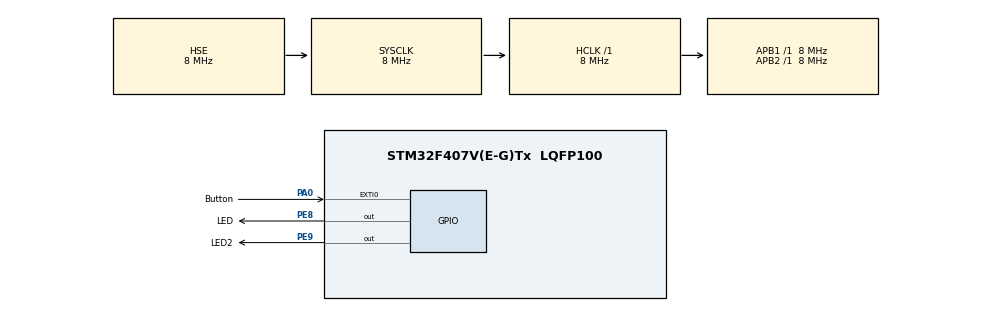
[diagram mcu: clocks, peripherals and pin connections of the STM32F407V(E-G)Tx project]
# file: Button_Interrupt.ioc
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Mcu.Family=STM32F4
Mcu.Name=STM32F407V(E-G)Tx
Mcu.Package=LQFP100
NVIC.EXTI0_IRQn=true\:0\:0\:false\:false\:true\:true\:true\:true
NVIC.PriorityGroup=NVIC_PRIORITYGROUP_4
PA0-WKUP.GPIO_Label=Button
PA0-WKUP.GPIO_ModeDefaultEXTI=GPIO_MODE_IT_RISING_FALLING
PA0-WKUP.GPIO_PuPd=GPIO_PULLDOWN
PA0-WKUP.Signal=GPXTI0
PA13.Mode=Serial_Wire
PA13.Signal=SYS_JTMS-SWDIO
PA14.Mode=Serial_Wire
PA14.Signal=SYS_JTCK-SWCLK
PE8.GPIO_Label=LED
PE8.Signal=GPIO_Output
PE9.GPIO_Label=LED2
PE9.Signal=GPIO_Output
PH0-OSC_IN.Mode=HSE-External-Oscillator
PH0-OSC_IN.Signal=RCC_OSC_IN
PH1-OSC_OUT.Mode=HSE-External-Oscillator
PH1-OSC_OUT.Signal=RCC_OSC_OUT
ProjectManager.HeapSize=0x200
ProjectManager.StackSize=0x400
ProjectManager.TargetToolchain=STM32CubeIDE
RCC.AHBFreq_Value=8000000
RCC.APB1Freq_Value=8000000
RCC.APB1TimFreq_Value=8000000
RCC.APB2Freq_Value=8000000
RCC.APB2TimFreq_Value=8000000
RCC.CortexFreq_Value=8000000
RCC.HCLKFreq_Value=8000000
RCC.HSE_VALUE=8000000
RCC.HSI_VALUE=16000000
RCC.LSE_VALUE=32768
RCC.SYSCLKFreq_VALUE=8000000
RCC.SYSCLKSource=RCC_SYSCLKSOURCE_HSE
RCC.VCOOutputFreq_Value=192000000
board=custom

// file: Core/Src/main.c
/* USER CODE BEGIN Header */
/**
  ******************************************************************************
  * @file           : main.c
  * @brief          : Main program body
  ******************************************************************************
  * @attention
  *
  * Copyright (c) 2023 STMicroelectronics.
  * All rights reserved.
  *
  * This software is licensed under terms that can be found in the LICENSE file
  * in the root directory of this software component.
  * If no LICENSE file comes with this software, it is provided AS-IS.
  *
  ******************************************************************************
  */
/* USER CODE END Header */
#include "main.h"

void SystemClock_Config(void);
static void MX_GPIO_Init(void);

int main(void)
{

  /* MCU Configuration--------------------------------------------------------*/

  /* Reset of all peripherals, Initializes the Flash interface and the Systick. */
  HAL_Init();

  /* Configure the system clock */
  SystemClock_Config();

  /* Initialize all configured peripherals */
  MX_GPIO_Init();

  /* Infinite loop */
  while (1)
  {

    /* USER CODE BEGIN 3 */
	  HAL_GPIO_WritePin(LED_GPIO_Port,LED_Pin,button_state);
  }
  /* USER CODE END 3 */
}

void SystemClock_Config(void)
{
  RCC_OscInitTypeDef RCC_OscInitStruct = {0};
  RCC_ClkInitTypeDef RCC_ClkInitStruct = {0};

  /** Configure the main internal regulator output voltage
  */
  __HAL_RCC_PWR_CLK_ENABLE();
  __HAL_PWR_VOLTAGESCALING_CONFIG(PWR_REGULATOR_VOLTAGE_SCALE1);

  /** Initializes the RCC Oscillators according to the specified parameters
  * in the RCC_OscInitTypeDef structure.
  */
  RCC_OscInitStruct.OscillatorType = RCC_OSCILLATORTYPE_HSE;
  RCC_OscInitStruct.HSEState = RCC_HSE_ON;
  RCC_OscInitStruct.PLL.PLLState = RCC_PLL_NONE;
  if (HAL_RCC_OscConfig(&RCC_OscInitStruct) != HAL_OK)
  {
    Error_Handler();
  }

  /** Initializes the CPU, AHB and APB buses clocks
  */
  RCC_ClkInitStruct.ClockType = RCC_CLOCKTYPE_HCLK|RCC_CLOCKTYPE_SYSCLK
                              |RCC_CLOCKTYPE_PCLK1|RCC_CLOCKTYPE_PCLK2;
  RCC_ClkInitStruct.SYSCLKSource = RCC_SYSCLKSOURCE_HSE;
  RCC_ClkInitStruct.AHBCLKDivider = RCC_SYSCLK_DIV1;
  RCC_ClkInitStruct.APB1CLKDivider = RCC_HCLK_DIV1;
  RCC_ClkInitStruct.APB2CLKDivider = RCC_HCLK_DIV1;

  if (HAL_RCC_ClockConfig(&RCC_ClkInitStruct, FLASH_LATENCY_0) != HAL_OK)
  {
    Error_Handler();
  }
}

static void MX_GPIO_Init(void)
{
  GPIO_InitTypeDef GPIO_InitStruct = {0};

  /* GPIO Ports Clock Enable */
  __HAL_RCC_GPIOH_CLK_ENABLE();
  __HAL_RCC_GPIOA_CLK_ENABLE();
  __HAL_RCC_GPIOE_CLK_ENABLE();

  /*Configure GPIO pin Output Level */
  HAL_GPIO_WritePin(GPIOE, LED_Pin|LED2_Pin, GPIO_PIN_RESET);

  /*Configure GPIO pin : Button_Pin */
  GPIO_InitStruct.Pin = Button_Pin;
  GPIO_InitStruct.Mode = GPIO_MODE_IT_RISING_FALLING;
  GPIO_InitStruct.Pull = GPIO_PULLDOWN;
  HAL_GPIO_Init(Button_GPIO_Port, &GPIO_InitStruct);

  /*Configure GPIO pins : LED_Pin LED2_Pin */
  GPIO_InitStruct.Pin = LED_Pin|LED2_Pin;
  GPIO_InitStruct.Mode = GPIO_MODE_OUTPUT_PP;
  GPIO_InitStruct.Pull = GPIO_NOPULL;
  GPIO_InitStruct.Speed = GPIO_SPEED_FREQ_LOW;
  HAL_GPIO_Init(GPIOE, &GPIO_InitStruct);

  /* EXTI interrupt init*/
  HAL_NVIC_SetPriority(EXTI0_IRQn, 0, 0);
  HAL_NVIC_EnableIRQ(EXTI0_IRQn);

}

void Error_Handler(void)
{
  __disable_irq();
  while (1)
  {
  }
}
